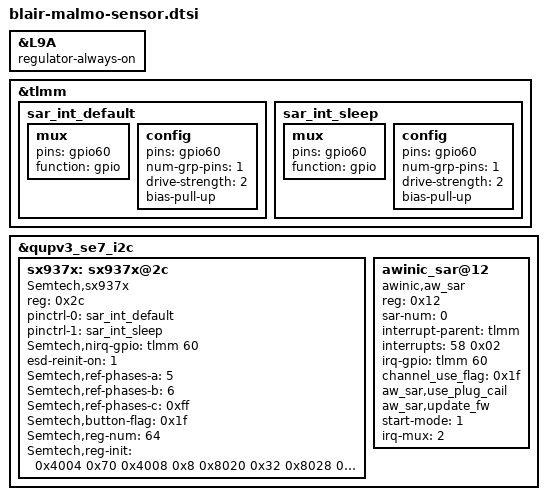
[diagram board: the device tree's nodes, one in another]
&L9A {
        regulator-always-on;
        status = "okay";
};

&tlmm {
        sar_int_default: sar_int_default {
                        mux {
                                pins = "gpio60";
                                function =  "gpio";
                        };
                        config {
                                pins = "gpio60";
                                num-grp-pins = <1>;
                                drive-strength = <2>;
                                bias-pull-up;
                        };
        };
        sar_int_sleep: sar_int_sleep {
                        mux {
                                pins = "gpio60";
                                function =  "gpio";
                        };
                        config {
                                pins = "gpio60";
                                num-grp-pins = <1>;
                                drive-strength = <2>;
                                bias-pull-up;
                        };
        };
};

&qupv3_se7_i2c {
        status = "okay";
        sx937x:sx937x@2c {
                compatible = "Semtech,sx937x";
                reg = <0x2c>;
                pinctrl-names = "default","sleep";
                pinctrl-0 = <&sar_int_default>;
                pinctrl-1 = <&sar_int_sleep>;
                //interrupt-parent = <&tlmm>;
                //interrupts = <24 0x02>;
                //interrupt-names = "sx937x_irq";
                Semtech,nirq-gpio = <&tlmm 60 0x02>;
                //cap_vdd-supply = <&pm6125_l12>;
                esd-reinit-on = <1>;
                /*use PH5/6 as the reference sensor
                set it to 0xff if the ref-phases-x is not used*/
                Semtech,ref-phases-a = <5>;
                Semtech,ref-phases-b = <6>;
                Semtech,ref-phases-c = <0xff>;
                Semtech,button-flag = <0x1f>;
                Semtech,reg-num = <64>;
                Semtech,reg-init = <
                          0x4004 0x70
                          0x4008 0x8
                          0x8020 0x32
                          0x8028 0x85E
                          0x8034 0x85E
                          0x8040 0x88E
                          0x804C 0x85E
                          0x8058 0x866
                          0x8064 0x85E
                          0x8070 0x85E
                          0x807C 0x85E
                          0x8030 0x924925
                          0x803C 0x925924
                          0x8048 0x964924
                          0x8054 0xB24924
                          0x8060 0x92C924
                          0x806C 0x92492C
                          0x8078 0x924964
                          0x8084 0xFFFFFF
                          0x8098 0x763C
                          0x80B8 0x2C2C
                          0x80D8 0x6464
                          0x80F8 0x2121
                          0x8118 0x4722
                          0x8138 0xFF
                          0x8158 0xFF
                          0x8178 0xC8
                          0x80A0 0x202000E1
                          0x80C0 0x202000E1
                          0x80E0 0x10100E2
                          0x8100 0x181800E2
                          0x8120 0x242400E2
                          0x8140 0xE0
                          0x8160 0xE0
                          0x8180 0x0
                          0x8188 0x8000015
                          0x818C 0x8000016
                          0x8190 0x0
                          0x8194 0x0
                          0x8090 0x5000
                          0x80B0 0x5000
                          0x80D0 0x5000
                          0x80F0 0x5000
                          0x8110 0x5000
                          0x8130 0x5000
                          0x8150 0x5000
                          0x8170 0x2AD66000
                          0x8088 0x300000
                          0x80A8 0x300000
                          0x80C8 0x300000
                          0x80E8 0x300000
                          0x8108 0x300000
                          0x8128 0x5300000
                          0x8148 0x5300000
                          0x8168 0x0
                          0x808C 0x60200018
                          0x80AC 0x60200018
                          0x80CC 0x60200018
                          0x80EC 0x60200018
                          0x810C 0x60200018
                          0x812C 0x60200018
                          0x814C 0x60200018
                          0x816C 0x60200018
                          0x8024 0x7F7F
                >;
                status = "ok";
        };
};

&qupv3_se7_i2c {
        status = "okay";
        awinic_sar@12 {
                /* common node */
                compatible = "awinic,aw_sar";
                reg = < 0x12 >;
                //aw_sar,regulator-power-supply = <1>;
                sar-num = < 0 >;
                interrupt-parent = < &tlmm >;
                interrupts = <58 0x02>;
                interrupt-names = "awinic_irq";
                irq-gpio = <&tlmm 60 0x02>;
                //vcc0-supply = <&L12A>;
                channel_use_flag = <0x1f>;
                aw_sar,use_plug_cail;
                aw_sar,update_fw;
                /* private node belongs to aw963xx */
                start-mode = < 1 >; // 0: start in rom  1: start in ram
                irq-mux = < 2 >; // set csx as irq pin. config this field when connect to aw96308/aw96310
                status = "okay";
        };

};
